# STM32F765BGT6 register map
File version: 1.0
Registers are 32-bit, access not given, reset 0x0 unless marked. A register's access mark holds for its fields unless they carry their own. Offsets are from the block's base; [hi:lo] are bit positions; 'fields as' and 'values as' point back to an identical list.

## USB_OTG_HS
Base 0x40040000
0x00 GOTGCTL
  [21] CURMOD, [20] OTGVER, [19] BSVLD, [18] ASVLD, [17] DBCT, [16] CIDSTS, [31:13] s, [12] EHEN, [11] DHNPEN, [10] HSHNPEN, [9] HNPRQ, [8] HNGSCS, [7] BVALOVAL, [6] BVALOEN, [5] AVALOVAL, [4] AVALOEN, [3] VBVALOVA, [2] VBVALOEN, [1] SRQ, [0] SRQSCS
0x04 GOTGINT
  [20] IDCHNG, [19] DBCDNE, [18] ADTOCHG, [17] HNGDET, [9] HNSSCHG, [8] SRSSCHG, [2] SEDET, [31:0] s
0x08 GAHBCFG
  [8] PTXFELVL, [7] TXFELVL, [31:6] s, [5] DMAEN, [4:1] HBSTLEN, [0] GINTMSK
0x0C GUSBCFG
  [30] FDMOD, [29] FHMOD, [25] ULPIIPD, [24] PTCI, [23] PCCI, [22] TSDPS, [21] ULPIEVBUSI, [20] ULPIEVBUSD, [19] ULPICSM, [18] ULPIAR, [17] ULPIFSL, [15] PHYLPC, [13:10] TRDT, [9] HNPCAP, [8] SRPCAP, [6] PHYSEL, [31:3] s, [2:0] TOCAL
0x10 GRSTCTL
  [31] AHBIDL, [30] DMAREQ, [10:6] TXFNUM, [5] TXFFLSH, [4] RXFFLSH, [29:2] s, [1] PSRST, [0] CSRST
0x14 GINTSTS
  [31] WKUPINT, [30] SRQINT, [29] DISCINT, [28] CIDSCHG, [26] PTXFE, [25] HCINT, [24] HPRTINT, [22] DATAFSUSP, [21] IPXFR/INCOMPISOOUT, [20] IISOIXFR, [19] OEPINT, [18] IEPINT, [15] EOPF, [14] ISOODRP, [13] ENUMDNE, [12] USBRST, [11] USBSUSP, [10] ESUSP, [27:8] s, [7] GONAKEFF, [6] GINAKEFF, [5] NPTXFE, [4] RXFLVL, [3] SOF, [2] OTGINT, [1] MMIS, [0] CMOD
0x18 GINTMSK
  [31] WUIM, [30] SRQIM, [29] DISCINT, [28] CIDSCHGM, [27] LPMINTM, [26] PTXFEM, [25] HCIM, [24] PRTIM, [23] RSTDETM, [22] FSUSPM, [21] IPXFRM/IISOOXFRM, [20] IISOIXFRM, [19] OEPINT, [18] IEPINT, [15] EOPFM, [14] ISOODRPM, [13] ENUMDNEM, [12] USBRST, [11] USBSUSPM, [10] ESUSPM, [7] GONAKEFFM, [6] GINAKEFFM, [5] NPTXFEM, [4] RXFLVLM, [3] SOFM, [2] OTGINT, [1] MMISM, [17:0] s
0x1C GRXSTSR
  [27] STSPHST, [31:25] s, [24:21] FRMNUM, [20:17] PKTSTS, [16:15] DPID, [14:4] BCNT, [3:0] EPNUM
0x20 GRXSTSP
  fields as GRXSTSR
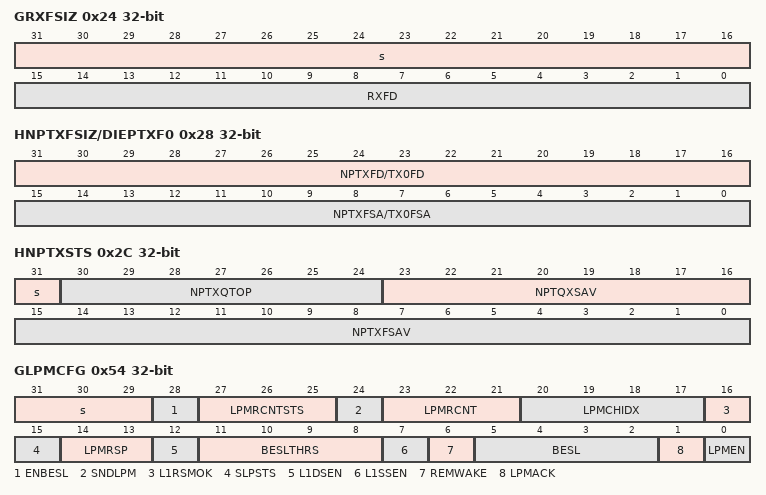
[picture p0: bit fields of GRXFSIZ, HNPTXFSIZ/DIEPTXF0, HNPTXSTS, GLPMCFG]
0x24 GRXFSIZ
  [31:16] s, [15:0] RXFD
0x28 HNPTXFSIZ/DIEPTXF0
  [31:16] NPTXFD/TX0FD, [15:0] NPTXFSA/TX0FSA
0x2C HNPTXSTS
  [31] s, [30:24] NPTXQTOP, [23:16] NPTQXSAV, [15:0] NPTXFSAV
0x38 GCCFG
  [21] VBDEN, [20] SDEN, [19] PDEN, [18] DCDEN, [17] BCDEN, [16] PWRDWN, [31:4] s, [3] PS2DET, [2] SDET, [1] PDET, [0] DCDET
0x3C CID
  [31:0] PRODUCT_ID
0x54 GLPMCFG
  [31:29] s, [28] ENBESL, [27:25] LPMRCNTSTS, [24] SNDLPM, [23:21] LPMRCNT, [20:17] LPMCHIDX, [16] L1RSMOK, [15] SLPSTS, [14:13] LPMRSP, [12] L1DSEN, [11:8] BESLTHRS, [7] L1SSEN, [6] REMWAKE, [5:2] BESL, [1] LPMACK, [0] LPMEN
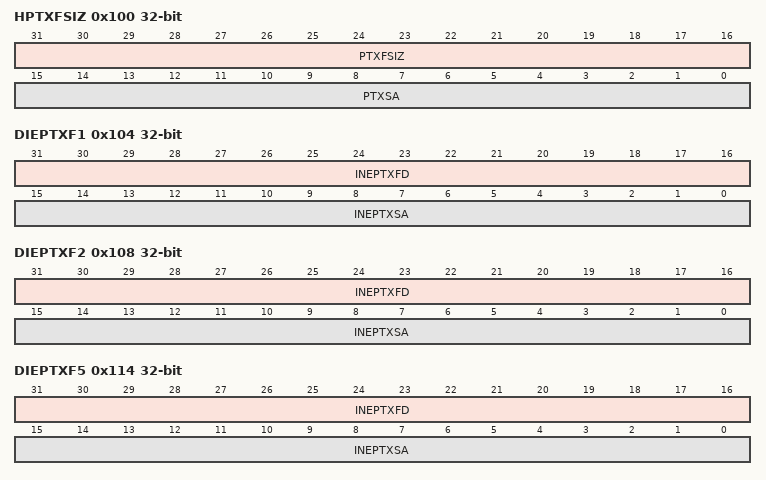
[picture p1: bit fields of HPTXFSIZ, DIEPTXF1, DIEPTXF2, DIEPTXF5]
0x100 HPTXFSIZ
  [31:16] PTXFSIZ, [15:0] PTXSA
0x104 DIEPTXF1
  [31:16] INEPTXFD, [15:0] INEPTXSA
0x108 DIEPTXF2
  [31:16] INEPTXFD, [15:0] INEPTXSA
0x114 DIEPTXF5
  [31:16] INEPTXFD, [15:0] INEPTXSA
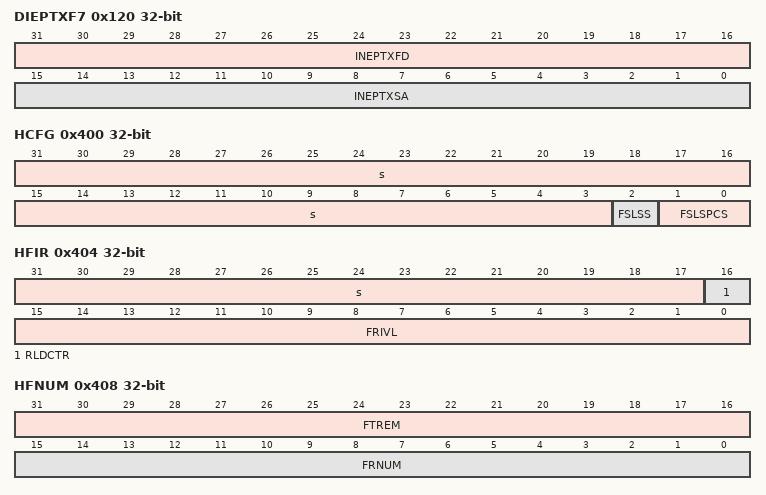
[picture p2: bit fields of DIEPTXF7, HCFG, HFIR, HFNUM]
0x120 DIEPTXF7
  [31:16] INEPTXFD, [15:0] INEPTXSA
0x400 HCFG
  [31:3] s, [2] FSLSS, [1:0] FSLSPCS
0x404 HFIR
  [31:17] s, [16] RLDCTR, [15:0] FRIVL
0x408 HFNUM
  [31:16] FTREM, [15:0] FRNUM
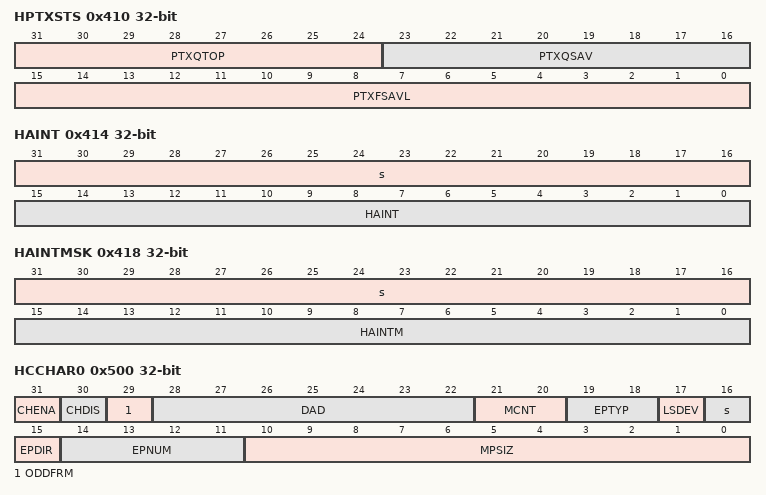
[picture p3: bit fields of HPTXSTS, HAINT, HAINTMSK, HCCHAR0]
0x410 HPTXSTS
  [31:24] PTXQTOP, [23:16] PTXQSAV, [15:0] PTXFSAVL
0x414 HAINT
  [31:16] s, [15:0] HAINT
0x418 HAINTMSK
  [31:16] s, [15:0] HAINTM
0x440 HPRT
  [18:17] PSPD, [16:13] PTCTL, [12] PPWR, [11:10] PLSTS, [31:9] s, [8] PRST, [7] PSUSP, [6] PRES, [5] POCCHNG, [4] POCA, [3] PENCHNG, [2] PENA, [1] PCDET, [0] PCSTS
0x500 HCCHAR0
  [31] CHENA, [30] CHDIS, [29] ODDFRM, [28:22] DAD, [21:20] MCNT, [19:18] EPTYP, [17] LSDEV, [16] s, [15] EPDIR, [14:11] EPNUM, [10:0] MPSIZ
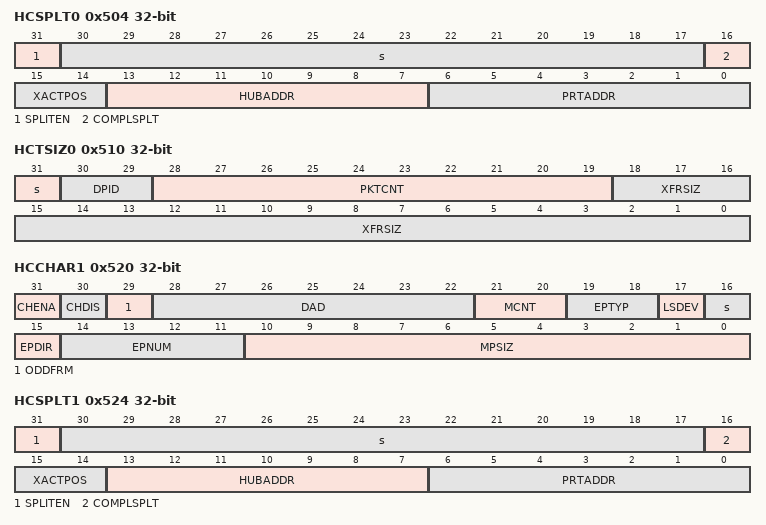
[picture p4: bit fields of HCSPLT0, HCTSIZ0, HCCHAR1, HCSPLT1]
0x504 HCSPLT0
  [31] SPLITEN, [30:17] s, [16] COMPLSPLT, [15:14] XACTPOS, [13:7] HUBADDR, [6:0] PRTADDR
0x508 HCINT0
  [10] DTERR, [9] FRMOR, [8] BBERR, [7] TXERR, [5] ACK, [4] NAK, [3] STALL, [31:2] s, [1] CHH, [0] XFRC
0x50C HCINTMSK0
  [10] DTERRM, [9] FRMORM, [8] BBERRM, [7] TXERRM, [6] NYET, [5] ACKM, [4] NAKM, [3] STALLM, [31:2] s, [1] CHHM, [0] XFRCM
0x510 HCTSIZ0
  [31] s, [30:29] DPID, [28:19] PKTCNT, [18:0] XFRSIZ
0x514 HCDMA0
  [31:0] DMAADDR
0x520 HCCHAR1
  fields as HCCHAR0
0x524 HCSPLT1
  fields as HCSPLT0
0x528 HCINT1
  fields as HCINT0
0x52C HCINTMSK1
  fields as HCINTMSK0
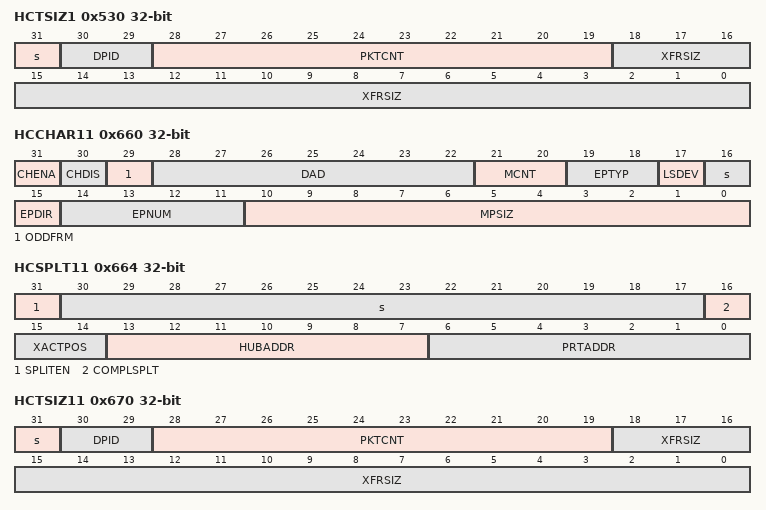
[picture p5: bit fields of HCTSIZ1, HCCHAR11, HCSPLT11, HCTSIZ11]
0x530 HCTSIZ1
  [31] s, [30:29] DPID, [28:19] PKTCNT, [18:0] XFRSIZ
0x534 HCDMA1
  [31:0] DMAADDR
0x660 HCCHAR11
  fields as HCCHAR0
0x664 HCSPLT11
  fields as HCSPLT0
0x668 HCINT11
  fields as HCINT0
0x66C HCINTMSK11
  fields as HCINTMSK0
0x670 HCTSIZ11
  [31] s, [30:29] DPID, [28:19] PKTCNT, [18:0] XFRSIZ
0x674 HCDMA11
  [31:0] DMAADDR
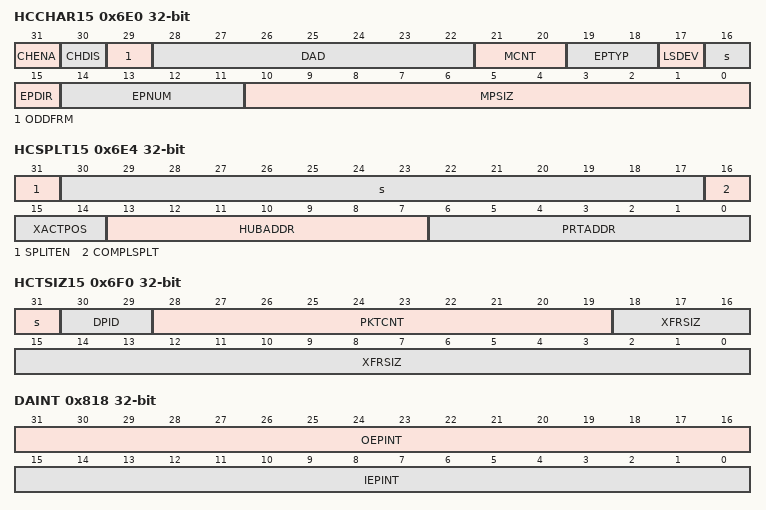
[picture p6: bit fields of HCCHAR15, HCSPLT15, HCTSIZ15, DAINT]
0x6E0 HCCHAR15
  fields as HCCHAR0
0x6E4 HCSPLT15
  fields as HCSPLT0
0x6E8 HCINT15
  fields as HCINT0
0x6EC HCINTMSK15
  fields as HCINTMSK0
0x6F0 HCTSIZ15
  [31] s, [30:29] DPID, [28:19] PKTCNT, [18:0] XFRSIZ
0x6F4 HCDMA15
  [31:0] DMAADDR
0x800 DCFG
  [15] ERRATIM, [14] XCVRDLY, [12:11] PFIVL, [10:4] DAD, [31:3] s, [2] NZLSOHSK, [1:0] DSPD
0x804 DCTL
  [18] DSBESLRJCT, [31:12] s, [11] POPRGDNE, [10] CGONAK, [9] SGONAK, [8] CGINAK, [7] SGINAK, [6:4] TCTL, [3] GONSTS, [2] GINSTS, [1] SDIS, [0] RWUSIG
0x808 DSTS
  [23:22] DEVLNSTS, [21:8] FNSOF, [31:4] s, [3] EERR, [2:1] ENUMSPD, [0] SUSPSTS
0x810 DIEPMSK
  [13] NAKM, [8] TXFURM, [31:7] s, [6] INEPNEM, [5] INEPNMM, [4] ITTXFEMSK, [3] TOM, [2] AHBERRM, [1] EPDM, [0] XFRCM
0x814 DOEPMSK
  [14] NYETMSK, [13] NAKMSK, [12] BERRM, [8] OUTPKTERRM, [6] B2BSTUPM, [31:5] s, [4] OTEPDM, [3] STUPM, [2] AHBERRM, [1] EPDM, [0] XFRCM
0x818 DAINT
  [31:16] OEPINT, [15:0] IEPINT
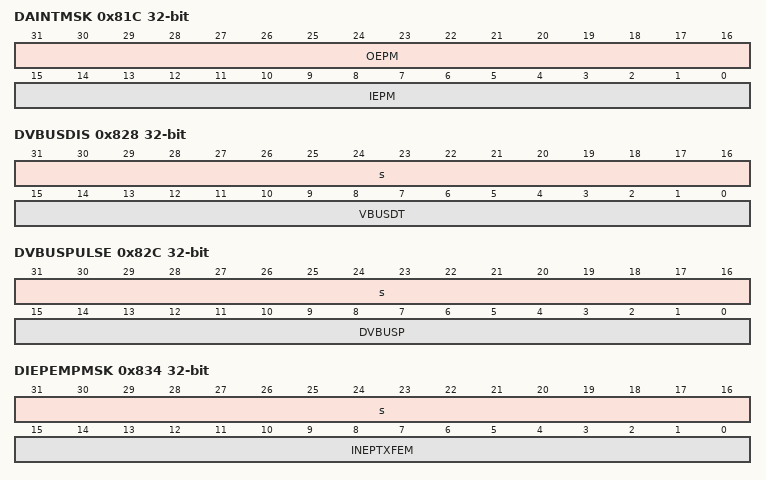
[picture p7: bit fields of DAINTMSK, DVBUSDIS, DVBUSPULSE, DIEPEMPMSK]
0x81C DAINTMSK
  [31:16] OEPM, [15:0] IEPM
0x828 DVBUSDIS
  [31:16] s, [15:0] VBUSDT
0x82C DVBUSPULSE
  [31:16] s, [15:0] DVBUSP
0x830 DTHRCTL
  [27] ARPEN, [25:17] RXTHRLEN, [16] RXTHREN, [31:12] s, [11:2] TXTHRLEN, [1] ISOTHREN, [0] NONISOTHREN
0x834 DIEPEMPMSK
  [31:16] s, [15:0] INEPTXFEM
0x838 DEACHINT
  [17] OEP1INT, [1] IEP1INT, [31:0] s
0x83C DEACHINTMSK
  [17] OEP1INTM, [1] IEP1INTM, [31:0] s
0x844 DIEPEACHMSK1
  [13] NAKM, [8] TXFURM, [6] INEPNEM, [31:5] s, [4] ITTXFEMSK, [3] TOM, [2] AHBERRM, [1] EPDM, [0] XFRCM
0x884 DOEPEACHMSK1
  fields as DOEPMSK
0x900 DIEPCTL0
  [31] EPENA, [30] EPDIS, [29] SODDFRM/SD1PID, [28] SD0PID/SEVNFRM, [27] SNAK, [26] CNAK, [25:22] TXFNUM, [21] STALL, [19:18] EPTYP, [17] NAKSTS, [16] EONUM/DPID, [15] USBAEP, [20:11] s, [10:0] MPSIZ
0x908 DIEPINT0
  [13] NAK, [11] PKTDRPSTS, [31:9] s, [8] TXFIFOUDRN, [7] TXFE, [6] INEPNE, [5] INEPNM, [4] ITTXFE, [3] TOC, [2] AHBERR, [1] EPDISD, [0] XFRC
0x910 DIEPTSIZ0
  [20:19] PKTCNT, [31:7] s, [6:0] XFRSIZ
0x914 DIEPDMA
  [31:0] DMAADDR
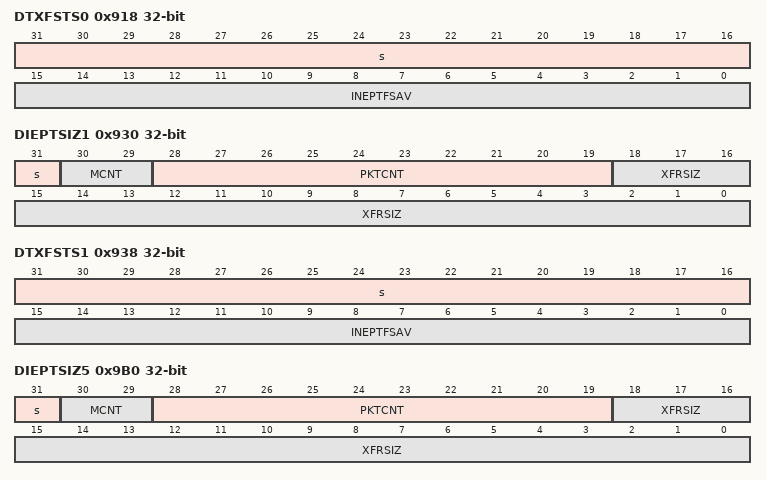
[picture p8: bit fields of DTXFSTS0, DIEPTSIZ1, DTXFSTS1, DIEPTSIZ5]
0x918 DTXFSTS0
  [31:16] s, [15:0] INEPTFSAV
0x920 DIEPCTL1
  fields as DIEPCTL0
0x928 DIEPINT1
  fields as DIEPINT0
0x930 DIEPTSIZ1
  [31] s, [30:29] MCNT, [28:19] PKTCNT, [18:0] XFRSIZ
0x938 DTXFSTS1
  [31:16] s, [15:0] INEPTFSAV
0x940 DIEPCTL2
  [31] EPENA, [30] EPDIS, [29] SODDFRM, [28] SD0PID/SEVNFRM, [27] SNAK, [26] CNAK, [25:22] TXFNUM, [21] STALL, [19:18] EPTYP, [17] NAKSTS, [16] EONUM/DPID, [15] USBAEP, [20:11] s, [10:0] MPSIZ
0x9A0 DIEPCTL5
  fields as DIEPCTL2
0x9A8 DIEPINT5
  fields as DIEPINT0
0x9B0 DIEPTSIZ5
  [31] s, [30:29] MCNT, [28:19] PKTCNT, [18:0] XFRSIZ
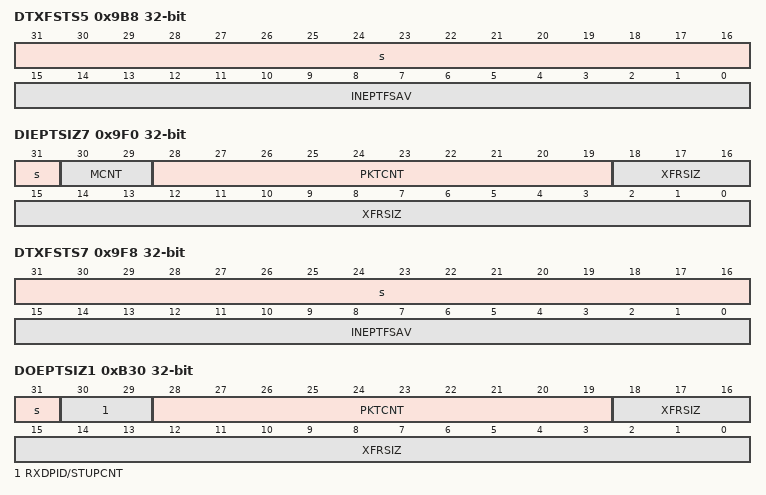
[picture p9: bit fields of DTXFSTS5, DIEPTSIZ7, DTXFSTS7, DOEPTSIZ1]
0x9B8 DTXFSTS5
  [31:16] s, [15:0] INEPTFSAV
0x9E0 DIEPCTL7
  fields as DIEPCTL2
0x9E8 DIEPINT7
  fields as DIEPINT0
0x9F0 DIEPTSIZ7
  [31] s, [30:29] MCNT, [28:19] PKTCNT, [18:0] XFRSIZ
0x9F8 DTXFSTS7
  [31:16] s, [15:0] INEPTFSAV
0xB00 DOEPCTL0
  [31] EPENA, [30] EPDIS, [27] SNAK, [26] CNAK, [21] STALL, [20] SNPM, [19:18] EPTYP, [17] NAKSTS, [15] USBAEP, [29:2] s, [1:0] MPSIZ
0xB08 DOEPINT0
  [15] STPKTRX, [14] NYET, [13] NAK, [12] BERR, [8] OUTPKTERR, [31:7] s, [6] B2BSTUP, [5] STSPHSRX, [4] OTEPDIS, [3] STUP, [2] AHBERR, [1] EPDISD, [0] XFRC
0xB10 DOEPTSIZ0
  [30:29] STUPCNT, [19] PKTCNT, [31:7] s, [6:0] XFRSIZ
0xB14 DOEPDMA0
  [31:0] DMAADDR
0xB20 DOEPCTL1
  [31] EPENA, [30] EPDIS, [29] SODDFRM, [28] SD0PID/SEVNFRM, [27] SNAK, [26] CNAK, [21] STALL, [20] SNPM, [19:18] EPTYP, [17] NAKSTS, [16] EONUM/DPID, [15] USBAEP, [25:11] s, [10:0] MPSIZ
0xB28 DOEPINT1
  fields as DOEPINT0
0xB30 DOEPTSIZ1
  [31] s, [30:29] RXDPID/STUPCNT, [28:19] PKTCNT, [18:0] XFRSIZ
0xB34 DOEPDMA1
  [31:0] DMAADDR
0xBA0 DOEPCTL5
  fields as DOEPCTL1
0xBA8 DOEPINT5
  fields as DOEPINT0
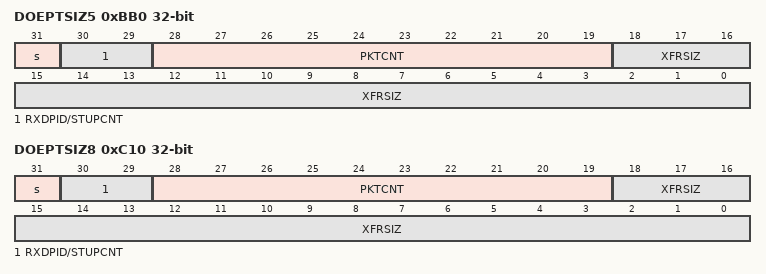
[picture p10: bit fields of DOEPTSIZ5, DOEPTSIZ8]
0xBB0 DOEPTSIZ5
  [31] s, [30:29] RXDPID/STUPCNT, [28:19] PKTCNT, [18:0] XFRSIZ
0xC00 DOEPCTL8
  fields as DOEPCTL1
0xC08 DOEPINT8
  fields as DOEPINT0
0xC10 DOEPTSIZ8
  [31] s, [30:29] RXDPID/STUPCNT, [28:19] PKTCNT, [18:0] XFRSIZ
0xC14 DOEPDMA8
  [31:0] DMAADDR
0xE00 PCGCCTL
  [7] SUSP, [6] PHYSLEEP, [5] ENL1GTG, [4] PHYSUSP, [31:2] s, [1] GATEHCLK, [0] STPPCLK

## USB_OTG_FS
Base 0x50000000
Registers as USB_OTG_HS, without DIEPEACHMSK1, DOEPEACHMSK1.
